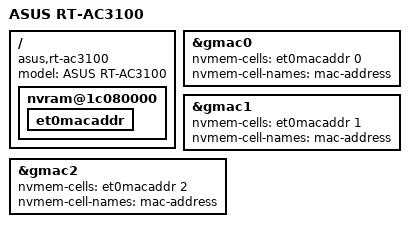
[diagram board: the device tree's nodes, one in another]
// SPDX-License-Identifier: GPL-2.0-or-later OR MIT
/*
 * Author: Arınç ÜNAL <arinc.unal@arinc9.com>
 */

/dts-v1/;

#include "bcm47094-asus-rt-ac3100.dtsi"

/ {
	compatible = "asus,rt-ac3100", "brcm,bcm47094", "brcm,bcm4708";
	model = "ASUS RT-AC3100";

	nvram@1c080000 {
		et0macaddr: et0macaddr {
			#nvmem-cell-cells = <1>;
		};
	};
};

&gmac0 {
	nvmem-cells = <&et0macaddr 0>;
	nvmem-cell-names = "mac-address";
};

&gmac1 {
	nvmem-cells = <&et0macaddr 1>;
	nvmem-cell-names = "mac-address";
};

&gmac2 {
	nvmem-cells = <&et0macaddr 2>;
	nvmem-cell-names = "mac-address";
};
